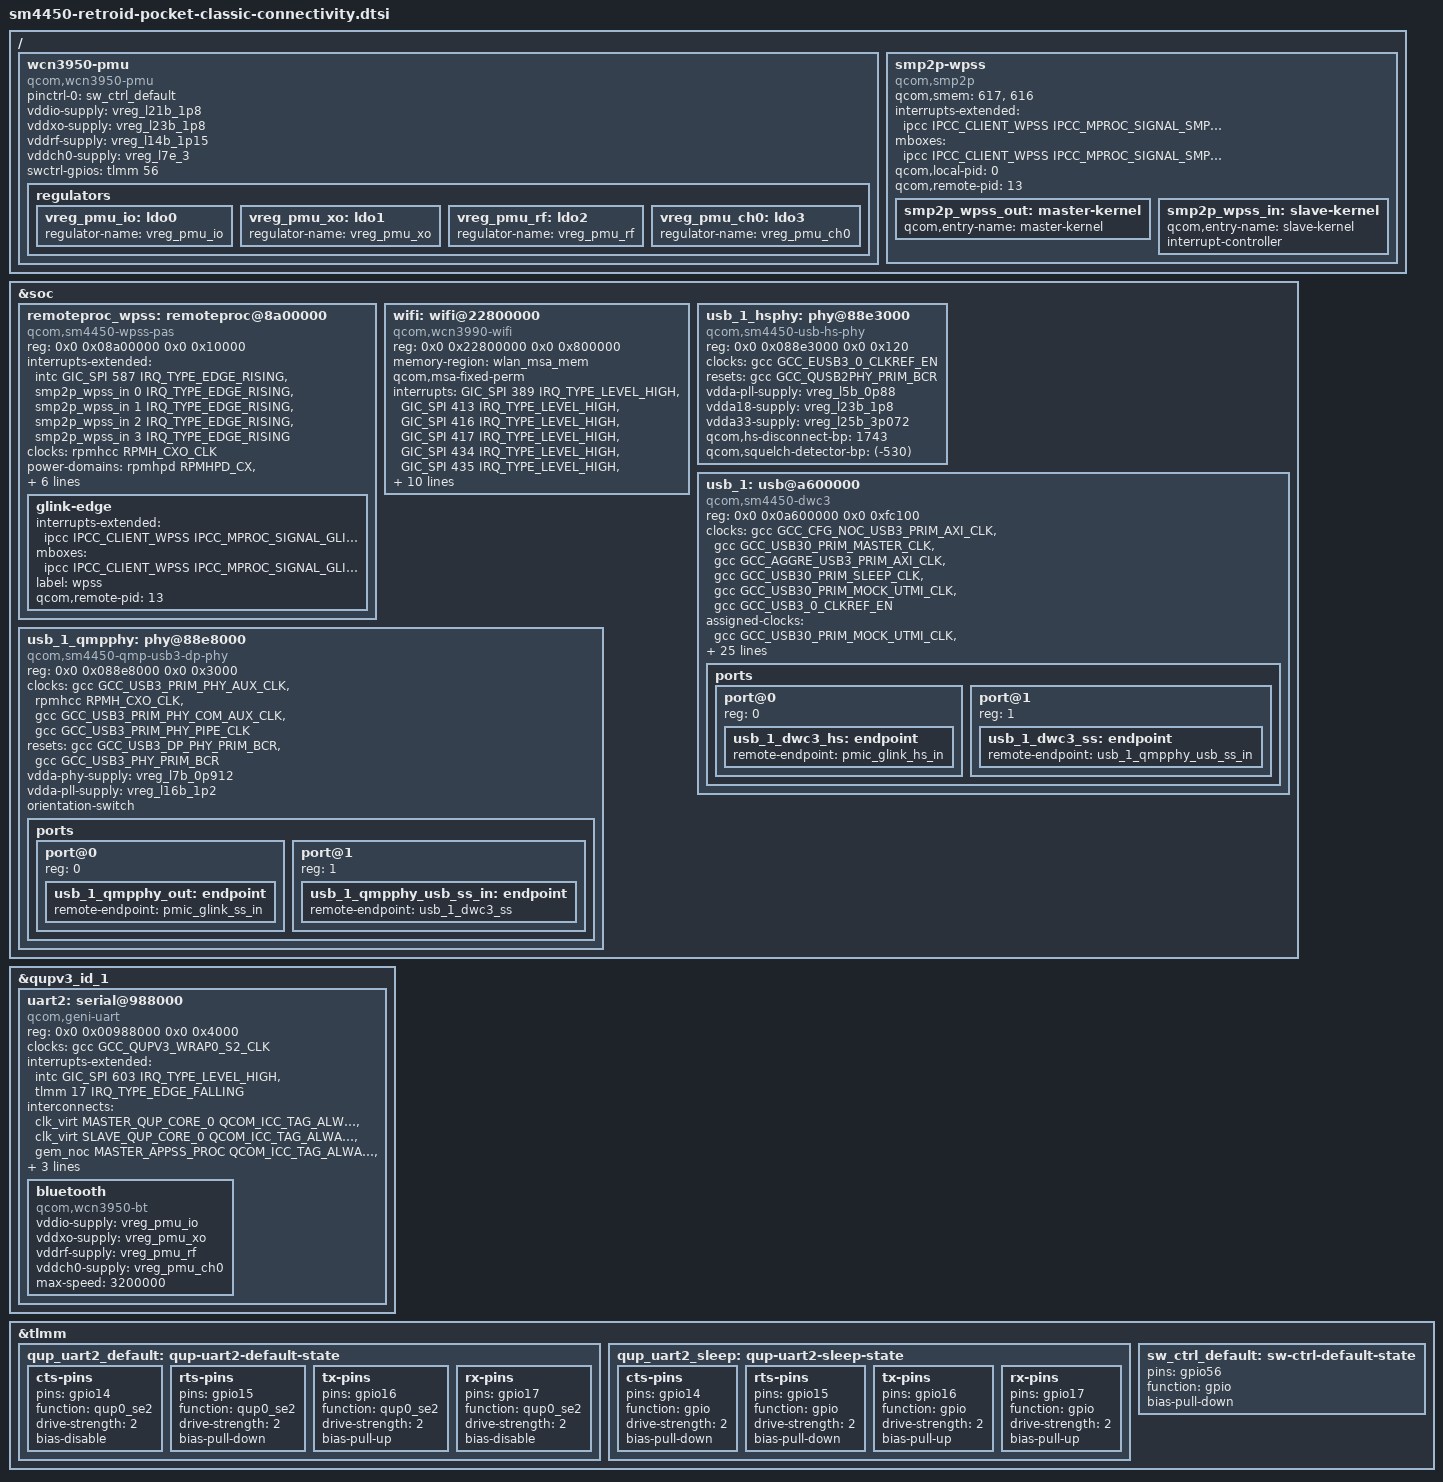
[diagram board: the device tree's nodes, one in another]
// SPDX-License-Identifier: BSD-3-Clause
/*
 * Copyright (C) 2026-present ROCKNIX (https://github.com/ROCKNIX).
 *
 * Retroid Pocket Classic (SM4450 "parrot"): connectivity.
 * Maintained by Banana as its own description of this handheld (it started as ROCKNIX's tree).
 *
 * The WCN3950 Wi-Fi and Bluetooth chip (power sequencer, the WPSS that runs its firmware, the
 * Bluetooth UART) and USB: the controller, both PHYs, and the Type-C port.
 * The Type-C port is run by the ADSP (pmic_glink, UCSI); the PM7250B Type-C and VBUS blocks stay
 * disabled. The FSA4480 mux on I2C8 (0x42) has no node: Banana builds no driver for it.
 *
 * Included from sm4450-retroid-pocket-classic-common.dtsi; do not include it on its own.
 */

/* ---- Wi-Fi and Bluetooth (WCN3950) ---- */

/ {
	wcn3950-pmu {
		compatible = "qcom,wcn3950-pmu";

		pinctrl-0 = <&sw_ctrl_default>;
		pinctrl-names = "default";

		vddio-supply = <&vreg_l21b_1p8>;
		vddxo-supply = <&vreg_l23b_1p8>;
		vddrf-supply = <&vreg_l14b_1p15>;
		vddch0-supply = <&vreg_l7e_3>;

		swctrl-gpios = <&tlmm 56 GPIO_ACTIVE_HIGH>;

		regulators {
			vreg_pmu_io: ldo0 {
				regulator-name = "vreg_pmu_io";
			};

			vreg_pmu_xo: ldo1 {
				regulator-name = "vreg_pmu_xo";
			};

			vreg_pmu_rf: ldo2 {
				regulator-name = "vreg_pmu_rf";
			};

			vreg_pmu_ch0: ldo3 {
				regulator-name = "vreg_pmu_ch0";
			};
		};
	};

	smp2p-wpss {
		compatible = "qcom,smp2p";
		qcom,smem = <617>, <616>;
		interrupts-extended = <&ipcc IPCC_CLIENT_WPSS
					     IPCC_MPROC_SIGNAL_SMP2P
					     IRQ_TYPE_EDGE_RISING>;
		mboxes = <&ipcc IPCC_CLIENT_WPSS IPCC_MPROC_SIGNAL_SMP2P>;
		qcom,local-pid = <0>;
		qcom,remote-pid = <13>;

		smp2p_wpss_out: master-kernel {
			qcom,entry-name = "master-kernel";
			#qcom,smem-state-cells = <1>;
		};

		smp2p_wpss_in: slave-kernel {
			qcom,entry-name = "slave-kernel";
			interrupt-controller;
			#interrupt-cells = <2>;
		};
	};
};

&soc {
	remoteproc_wpss: remoteproc@8a00000 {
		compatible = "qcom,sm4450-wpss-pas";
		reg = <0x0 0x08a00000 0x0 0x10000>;

		interrupts-extended = <&intc GIC_SPI 587 IRQ_TYPE_EDGE_RISING>,
				      <&smp2p_wpss_in 0 IRQ_TYPE_EDGE_RISING>,
				      <&smp2p_wpss_in 1 IRQ_TYPE_EDGE_RISING>,
				      <&smp2p_wpss_in 2 IRQ_TYPE_EDGE_RISING>,
				      <&smp2p_wpss_in 3 IRQ_TYPE_EDGE_RISING>;
		interrupt-names = "wdog", "fatal", "ready",
				  "handover", "stop-ack";

		clocks = <&rpmhcc RPMH_CXO_CLK>;
		clock-names = "xo";

		power-domains = <&rpmhpd RPMHPD_CX>,
				<&rpmhpd RPMHPD_MX>;
		power-domain-names = "cx", "mx";

		memory-region = <&wpss_mem>;

		qcom,qmp = <&aoss_qmp>;
		qcom,smem-states = <&smp2p_wpss_out 0>;
		qcom,smem-state-names = "stop";

		firmware-name = "qcom/sm4450/RPClassic/wpss.mbn";

		glink-edge {
			interrupts-extended = <&ipcc IPCC_CLIENT_WPSS
						     IPCC_MPROC_SIGNAL_GLINK_QMP
						     IRQ_TYPE_EDGE_RISING>;
			mboxes = <&ipcc IPCC_CLIENT_WPSS
					IPCC_MPROC_SIGNAL_GLINK_QMP>;
			label = "wpss";
			qcom,remote-pid = <13>;
		};
	};

	wifi: wifi@22800000 {
		compatible = "qcom,wcn3990-wifi";
		reg = <0x0 0x22800000 0x0 0x800000>;
		reg-names = "membase";
		memory-region = <&wlan_msa_mem>;

		qcom,msa-fixed-perm;

		interrupts = <GIC_SPI 389 IRQ_TYPE_LEVEL_HIGH>,
			     <GIC_SPI 413 IRQ_TYPE_LEVEL_HIGH>,
			     <GIC_SPI 416 IRQ_TYPE_LEVEL_HIGH>,
			     <GIC_SPI 417 IRQ_TYPE_LEVEL_HIGH>,
			     <GIC_SPI 434 IRQ_TYPE_LEVEL_HIGH>,
			     <GIC_SPI 435 IRQ_TYPE_LEVEL_HIGH>,
			     <GIC_SPI 438 IRQ_TYPE_LEVEL_HIGH>,
			     <GIC_SPI 439 IRQ_TYPE_LEVEL_HIGH>,
			     <GIC_SPI 440 IRQ_TYPE_LEVEL_HIGH>,
			     <GIC_SPI 451 IRQ_TYPE_LEVEL_HIGH>,
			     <GIC_SPI 453 IRQ_TYPE_LEVEL_HIGH>,
			     <GIC_SPI 454 IRQ_TYPE_LEVEL_HIGH>;

		iommus = <&apps_smmu 0x4c0 0x1>;

		vdd-1.8-xo-supply = <&vreg_l23b_1p8>;
		vdd-1.3-rfa-supply = <&vreg_l14b_1p15>;
		vdd-3.3-ch0-supply = <&vreg_l7e_3>;


		status = "okay";
	};
};

&qupv3_id_1 {
	uart2: serial@988000 {
		compatible = "qcom,geni-uart";
		reg = <0x0 0x00988000 0x0 0x4000>;
		clocks = <&gcc GCC_QUPV3_WRAP0_S2_CLK>;
		clock-names = "se";
		interrupts-extended = <&intc GIC_SPI 603 IRQ_TYPE_LEVEL_HIGH>,
				      <&tlmm 17 IRQ_TYPE_EDGE_FALLING>;
		interconnects = <&clk_virt MASTER_QUP_CORE_0 QCOM_ICC_TAG_ALWAYS
				 &clk_virt SLAVE_QUP_CORE_0 QCOM_ICC_TAG_ALWAYS>,
				<&gem_noc MASTER_APPSS_PROC QCOM_ICC_TAG_ALWAYS
				 &config_noc SLAVE_QUP_0 QCOM_ICC_TAG_ALWAYS>;
		interconnect-names = "qup-core", "qup-config";
		pinctrl-0 = <&qup_uart2_default>;
		pinctrl-1 = <&qup_uart2_sleep>;
		pinctrl-names = "default", "sleep";
		status = "okay";

		bluetooth: bluetooth {
			compatible = "qcom,wcn3950-bt";

			vddio-supply = <&vreg_pmu_io>;
			vddxo-supply = <&vreg_pmu_xo>;
			vddrf-supply = <&vreg_pmu_rf>;
			vddch0-supply = <&vreg_pmu_ch0>;
			max-speed = <3200000>;
		};
	};
};

&tlmm {
	qup_uart2_default: qup-uart2-default-state {
		cts-pins {
			pins = "gpio14";
			function = "qup0_se2";
			drive-strength = <2>;
			bias-disable;
		};

		rts-pins {
			pins = "gpio15";
			function = "qup0_se2";
			drive-strength = <2>;
			bias-pull-down;
		};

		tx-pins {
			pins = "gpio16";
			function = "qup0_se2";
			drive-strength = <2>;
			bias-pull-up;
		};

		rx-pins {
			pins = "gpio17";
			function = "qup0_se2";
			drive-strength = <2>;
			bias-disable;
		};
	};

	qup_uart2_sleep: qup-uart2-sleep-state {
		cts-pins {
			pins = "gpio14";
			function = "gpio";
			drive-strength = <2>;
			bias-pull-down;
		};

		rts-pins {
			pins = "gpio15";
			function = "gpio";
			drive-strength = <2>;
			bias-pull-down;
		};

		tx-pins {
			pins = "gpio16";
			function = "gpio";
			drive-strength = <2>;
			bias-pull-up;
		};

		rx-pins {
			pins = "gpio17";
			function = "gpio";
			drive-strength = <2>;
			bias-pull-up;
		};
	};

	sw_ctrl_default: sw-ctrl-default-state {
		pins = "gpio56";
		function = "gpio";
		bias-pull-down;
	};
};

/* ---- USB ---- */

&soc {
	usb_1_hsphy: phy@88e3000 {
		compatible = "qcom,sm4450-usb-hs-phy",
			     "qcom,usb-snps-hs-7nm-phy";
		reg = <0x0 0x088e3000 0x0 0x120>;
		#phy-cells = <0>;
		clocks = <&gcc GCC_EUSB3_0_CLKREF_EN>;
		clock-names = "ref";
		resets = <&gcc GCC_QUSB2PHY_PRIM_BCR>;
		vdda-pll-supply = <&vreg_l5b_0p88>;
		vdda18-supply = <&vreg_l23b_1p8>;
		vdda33-supply = <&vreg_l25b_3p072>;

		qcom,hs-disconnect-bp = <1743>;
		qcom,squelch-detector-bp = <(-530)>;
	};

	usb_1: usb@a600000 {
		compatible = "qcom,sm4450-dwc3", "qcom,snps-dwc3";
		reg = <0x0 0x0a600000 0x0 0xfc100>;

		clocks = <&gcc GCC_CFG_NOC_USB3_PRIM_AXI_CLK>,
			 <&gcc GCC_USB30_PRIM_MASTER_CLK>,
			 <&gcc GCC_AGGRE_USB3_PRIM_AXI_CLK>,
			 <&gcc GCC_USB30_PRIM_SLEEP_CLK>,
			 <&gcc GCC_USB30_PRIM_MOCK_UTMI_CLK>,
			 <&gcc GCC_USB3_0_CLKREF_EN>;
		clock-names = "cfg_noc",
			      "core",
			      "iface",
			      "sleep",
			      "mock_utmi",
			      "xo";

		assigned-clocks = <&gcc GCC_USB30_PRIM_MOCK_UTMI_CLK>,
				  <&gcc GCC_USB30_PRIM_MASTER_CLK>;
		assigned-clock-rates = <19200000>, <133333333>;

		interrupts-extended = <&intc GIC_SPI 133 IRQ_TYPE_LEVEL_HIGH>,
				      <&intc GIC_SPI 130 IRQ_TYPE_LEVEL_HIGH>,
				      <&intc GIC_SPI 131 IRQ_TYPE_LEVEL_HIGH>,
				      <&pdc 14 IRQ_TYPE_EDGE_BOTH>,
				      <&pdc 15 IRQ_TYPE_EDGE_BOTH>,
				      <&pdc 17 IRQ_TYPE_LEVEL_HIGH>;
		interrupt-names = "dwc_usb3",
				  "pwr_event",
				  "hs_phy_irq",
				  "dp_hs_phy_irq",
				  "dm_hs_phy_irq",
				  "ss_phy_irq";

		power-domains = <&gcc GCC_USB30_PRIM_GDSC>;

		resets = <&gcc GCC_USB30_PRIM_BCR>;

		interconnects = <&aggre2_noc MASTER_USB3_0 QCOM_ICC_TAG_ALWAYS
				 &mc_virt SLAVE_EBI1 QCOM_ICC_TAG_ALWAYS>,
				<&gem_noc MASTER_APPSS_PROC QCOM_ICC_TAG_ALWAYS
				 &config_noc SLAVE_USB3_0 QCOM_ICC_TAG_ALWAYS>;
		interconnect-names = "usb-ddr", "apps-usb";

		iommus = <&apps_smmu 0x540 0x0>;
		snps,dis_u2_susphy_quirk;
		snps,dis_enblslpm_quirk;
		snps,dis_u3_susphy_quirk;

		phys = <&usb_1_hsphy>,
		       <&usb_1_qmpphy QMP_USB43DP_USB3_PHY>;
		phy-names = "usb2-phy", "usb3-phy";
		dr_mode = "otg";
		usb-role-switch;
		role-switch-default-mode = "peripheral";

		ports {
			#address-cells = <1>;
			#size-cells = <0>;

			port@0 {
				reg = <0>;

				usb_1_dwc3_hs: endpoint {
					remote-endpoint = <&pmic_glink_hs_in>;
				};
			};

			port@1 {
				reg = <1>;

				usb_1_dwc3_ss: endpoint {
					remote-endpoint = <&usb_1_qmpphy_usb_ss_in>;
				};
			};
		};
	};

	usb_1_qmpphy: phy@88e8000 {
		compatible = "qcom,sm4450-qmp-usb3-dp-phy";
		reg = <0x0 0x088e8000 0x0 0x3000>;

		clocks = <&gcc GCC_USB3_PRIM_PHY_AUX_CLK>,
			 <&rpmhcc RPMH_CXO_CLK>,
			 <&gcc GCC_USB3_PRIM_PHY_COM_AUX_CLK>,
			 <&gcc GCC_USB3_PRIM_PHY_PIPE_CLK>;
		clock-names = "aux", "ref", "com_aux", "usb3_pipe";

		resets = <&gcc GCC_USB3_DP_PHY_PRIM_BCR>,
			 <&gcc GCC_USB3_PHY_PRIM_BCR>;
		reset-names = "phy", "common";

		#clock-cells = <1>;
		#phy-cells = <1>;

		vdda-phy-supply = <&vreg_l7b_0p912>;
		vdda-pll-supply = <&vreg_l16b_1p2>;

		orientation-switch;

		ports {
			#address-cells = <1>;
			#size-cells = <0>;

			port@0 {
				reg = <0>;

				usb_1_qmpphy_out: endpoint {
					remote-endpoint = <&pmic_glink_ss_in>;
				};
			};

			port@1 {
				reg = <1>;

				usb_1_qmpphy_usb_ss_in: endpoint {
					remote-endpoint = <&usb_1_dwc3_ss>;
				};
			};
		};
	};
};
